# AT32F407xx register map
Vendor: Keil; Series: AT32F407; File version: 1.0
CPU: CM4 r0p1, little endian, no MPU, FPU, 4 interrupt priority bits
Registers are 32-bit, read-write, reset 0x0 unless marked. A register's access mark holds for its fields unless they carry their own. Offsets are from the block's base; [hi:lo] are bit positions.

## ETHERNET_MAC — Ethernet: media access control
Base 0x40028000
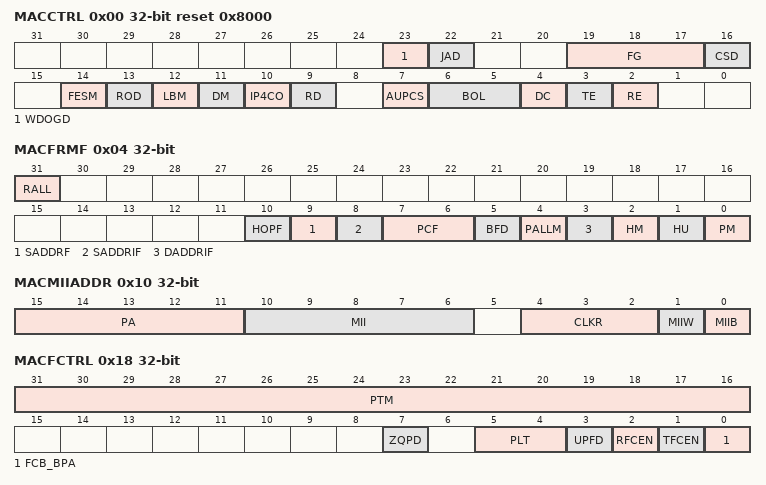
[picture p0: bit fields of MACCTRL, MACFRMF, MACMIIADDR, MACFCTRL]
0x00 MACCTRL reset 0x8000 — Ethernet MAC configuration register (ETH_MACCTRL)
  [23] WDOGD — Watchdog disable
  [22] JAD — Jabber disable
  [19:17] FG — Interframe gap
  [16] CSD — Carrier sense disable
  [14] FESM — Fast Ethernet speed
  [13] ROD — Receive own disable
  [12] LBM — Loopback mode
  [11] DM — Duplex mode
  [10] IP4CO — IPv4 checksum offload
  [9] RD — Retry disable
  [7] AUPCS — Automatic pad/CRC stripping
  [6:5] BOL — Back-off limit
  [4] DC — Deferral check
  [3] TE — Transmitter enable
  [2] RE — Receiver enable
0x04 MACFRMF — Ethernet MAC frame filter register (ETH_MACFRMF)
  [31] RALL — Receive all
  [10] HOPF — Hash or perfect filter
  [9] SADDRF — Source address filter
  [8] SADDRIF — Source address inverse filtering
  [7:6] PCF — Pass control frames
  [5] BFD — Broadcast frames disable
  [4] PALLM — Pass all multicast
  [3] DADDRIF — Destination address inverse filtering
  [2] HM — Hash multicast
  [1] HU — Hash unicast
  [0] PM — Promiscuous mode
0x08 MACHTH — Ethernet MAC hash table high register
  [31:0] HTH — Hash table high
0x0C MACHTL — Ethernet MAC hash table low register
  [31:0] HTL — Hash table low
0x10 MACMIIADDR — Ethernet MAC MII address register (ETH_MACMIIADDR)
  [15:11] PA — PHY address
  [10:6] MII
  [4:2] CLKR — Clock range
  [1] MIIW — MII write
  [0] MIIB — MII busy
0x14 MACMIIDT — Ethernet MAC MII data register (ETH_MACMIIDT)
  [15:0] MIID — MII data
0x18 MACFCTRL — Ethernet MAC flow control register (ETH_MACFCTRL)
  [31:16] PTM — Pass control frames
  [7] ZQPD — Zero-quanta pause disable
  [5:4] PLT — Pause low threshold
  [3] UPFD — Unicast pause frame detect
  [2] RFCEN — Receive flow control enable
  [1] TFCEN — Transmit flow control enable
  [0] FCB_BPA — Flow control busy/back pressure activate
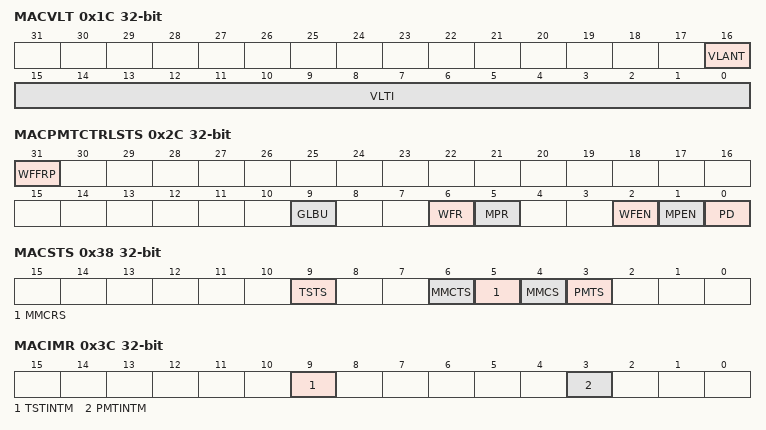
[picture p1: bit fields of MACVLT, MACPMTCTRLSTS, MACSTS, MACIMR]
0x1C MACVLT — Ethernet MAC VLAN tag register (ETH_MACVLT)
  [16] VLANT — 12-bit VLAN tag comparison
  [15:0] VLTI — VLAN tag identifier (for receive frames)
0x28 MACRWFF — Ethernet MAC remote wakeup frame filter register (ETH_MACRWFF)
0x2C MACPMTCTRLSTS — Ethernet MAC PMT control and status register (ETH_MACPMTCTRLSTS)
  [31] WFFRP — Wakeup frame filter register pointer reset
  [9] GLBU — Global unicast
  [6] WFR — Wakeup frame received
  [5] MPR — Magic packet received
  [2] WFEN — Wakeup frame enable
  [1] MPEN — Magic Packet enable
  [0] PD — Power down
0x38 MACSTS — Ethernet MAC interrupt status register (ETH_MACSTS)
  [9] TSTS — Time stamp trigger status
  [6] MMCTS — MMC transmit status
  [5] MMCRS — MMC receive status
  [4] MMCS — MMC status
  [3] PMTS — PMT status
0x3C MACIMR — Ethernet MAC interrupt mask register (ETH_MACIMR)
  [9] TSTINTM — Time stamp trigger interrupt mask
  [3] PMTINTM — PMT interrupt mask
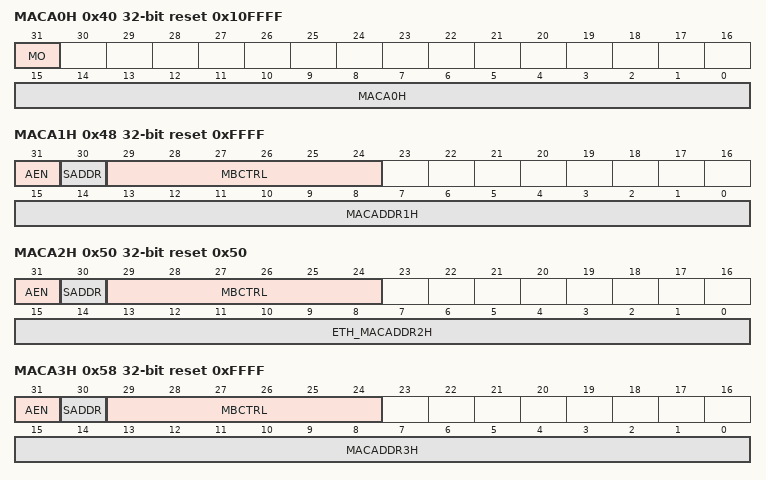
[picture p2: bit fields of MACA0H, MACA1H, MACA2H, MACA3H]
0x40 MACA0H reset 0x10FFFF — Ethernet MAC address 0 high register (ETH_MACA0H)
  [31] MO ro — Always 1
  [15:0] MACA0H — MAC address0 high
0x44 MACA0L reset 0xFFFFFFFF — Ethernet MAC address 0 low register
  [31:0] MACA0L — MAC address0 low
0x48 MACA1H reset 0xFFFF — Ethernet MAC address 1 high register (ETH_MACA1H)
  [31] AEN — Address enable
  [30] SADDR — Source address
  [29:24] MBCTRL — Mask byte control
  [15:0] MACADDR1H — MAC address1 high
0x4C MACA1L reset 0xFFFFFFFF — Ethernet MAC address1 low register
  [31:0] MACADDR1L — MAC address1 low
0x50 MACA2H reset 0x50 — Ethernet MAC address 2 high register (ETH_MACA2H)
  [31] AEN — Address enable
  [30] SADDR — Source address
  [29:24] MBCTRL — Mask byte control
  [15:0] ETH_MACADDR2H — Ethernet MAC address 2 high register
0x54 MACA2L reset 0xFFFFFFFF — Ethernet MAC address 2 low register
  [30:0] MACA2L — MAC address2 low
0x58 MACA3H reset 0xFFFF — Ethernet MAC address 3 high register (ETH_MACA3H)
  [31] AEN — Address enable
  [30] SADDR — Source address
  [29:24] MBCTRL — Mask byte control
  [15:0] MACADDR3H — MAC address3 high
0x5C MACA3L reset 0xFFFFFFFF — Ethernet MAC address 3 low register
  [31:0] MBCA3L — MAC address3 low

## Notices in the file
Copyright (C) 2012-2014 ARM Limited. All rights reserved.
Purpose: System Viewer Description (SVD) Example (Schema Version 1.1)
This is a description of a none-existent and incomplete device
for demonstration purposes only.
Redistribution and use in source and binary forms, with or without
modification, are permitted provided that the following conditions are met:
- Redistributions of source code must retain the above copyright
notice, this list of conditions and the following disclaimer.
- Redistributions in binary form must reproduce the above copyright
notice, this list of conditions and the following disclaimer in the
documentation and/or other materials provided with the distribution.
- Neither the name of ARM nor the names of its contributors may be used
to endorse or promote products derived from this software without
specific prior written permission.
THIS SOFTWARE IS PROVIDED BY THE COPYRIGHT HOLDERS AND CONTRIBUTORS "AS IS"
AND ANY EXPRESS OR IMPLIED WARRANTIES, INCLUDING, BUT NOT LIMITED TO, THE
IMPLIED WARRANTIES OF MERCHANTABILITY AND FITNESS FOR A PARTICULAR PURPOSE
ARE DISCLAIMED. IN NO EVENT SHALL COPYRIGHT HOLDERS AND CONTRIBUTORS BE
LIABLE FOR ANY DIRECT, INDIRECT, INCIDENTAL, SPECIAL, EXEMPLARY, OR
CONSEQUENTIAL DAMAGES (INCLUDING, BUT NOT LIMITED TO, PROCUREMENT OF
SUBSTITUTE GOODS OR SERVICES; LOSS OF USE, DATA, OR PROFITS; OR BUSINESS
INTERRUPTION) HOWEVER CAUSED AND ON ANY THEORY OF LIABILITY, WHETHER IN
CONTRACT, STRICT LIABILITY, OR TORT (INCLUDING NEGLIGENCE OR OTHERWISE)
ARISING IN ANY WAY OUT OF THE USE OF THIS SOFTWARE, EVEN IF ADVISED OF THE
POSSIBILITY OF SUCH DAMAGE.
